AUTOSAR XML (schema 314)
package /ComponentType
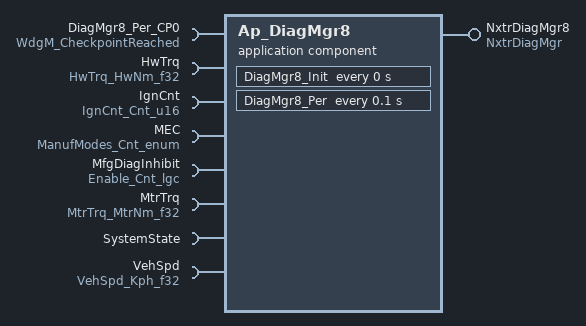
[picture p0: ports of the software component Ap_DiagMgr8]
  application software component type Ap_DiagMgr8
    provide port NxtrDiagMgr8: provided-interface=NxtrDiagMgr
      provided-com-specs:
        operation=GetNTCActive, queue-length=1
        operation=GetNTCFailed, queue-length=1
        operation=GetNTCStatus, queue-length=1
        operation=SetNTCStatus, queue-length=1
    8 x require port:
      DiagMgr8_Per_CP0: client-com-spec=CheckpointReached, required-interface=WdgM_CheckpointReached
      HwTrq: unqueued-receiver-com-spec{data-element=HwNm_f32, init-value=D_ZERO_ULS_F32}, required-interface=HwTrq_HwNm_f32
      IgnCnt: unqueued-receiver-com-spec{data-element=Cnt_u16, init-value=D_ZERO_CNT_U16}, required-interface=IgnCnt_Cnt_u16
      MEC: unqueued-receiver-com-spec{data-element=Cnt_enum, init-value=D_MANUFMODEINIT_CNT_ENUM}, required-interface=ManufModes_Cnt_enum
      MfgDiagInhibit: unqueued-receiver-com-spec{data-element=Cnt_lgc, init-value=D_FALSE_CNT_LGC}, required-interface=Enable_Cnt_lgc
      MtrTrq: unqueued-receiver-com-spec{data-element=MtrNm_f32, init-value=D_ZERO_ULS_F32}, required-interface=MtrTrq_MtrNm_f32
      SystemState: required-interface=SystemState
      VehSpd: unqueued-receiver-com-spec{data-element=Kph_f32, init-value=D_ZERO_ULS_F32}, required-interface=VehSpd_Kph_f32
  internal behavior Ap_DiagMgr8_InternalBehavior: component=Ap_DiagMgr8
    timing event DiagMgr8_InitEvent: start-on-event=DiagMgr8_Init, period=0
    timing event TMT_DiagMgr8_Per: start-on-event=DiagMgr8_Per, period=0.1
    mode switch event MST_DiagMgr8_Trns_0: start-on-event=DiagMgr8_Trns, activation=EXIT, mode=SystemState.Mode.OFF
    4 x operation invoked event:
      OIT_NxtrDiagMgr8_GetNTCActive_NxtrDiagMgr8_GetNTCActive: start-on-event=NxtrDiagMgr8_GetNTCActive, operation=NxtrDiagMgr8.GetNTCActive
      OIT_NxtrDiagMgr8_GetNTCFailed_NxtrDiagMgr8_GetNTCFailed: start-on-event=NxtrDiagMgr8_GetNTCFailed, operation=NxtrDiagMgr8.GetNTCFailed
      OIT_NxtrDiagMgr8_GetNTCStatus_NxtrDiagMgr8_GetNTCStatus: start-on-event=NxtrDiagMgr8_GetNTCStatus, operation=NxtrDiagMgr8.GetNTCStatus
      OIT_NxtrDiagMgr8_SetNTCStatus_NxtrDiagMgr8_SetNTCStatus: start-on-event=NxtrDiagMgr8_SetNTCStatus, operation=NxtrDiagMgr8.SetNTCStatus
    port-api-options:
      enable-take-address=false, indirect-api=false, port=DiagMgr8_Per_CP0
      enable-take-address=false, indirect-api=false, port=HwTrq
      enable-take-address=false, indirect-api=false, port=IgnCnt
      enable-take-address=false, indirect-api=false, port=MEC
      enable-take-address=false, indirect-api=false, port=MfgDiagInhibit
      enable-take-address=false, indirect-api=false, port=MtrTrq
      enable-take-address=false, indirect-api=false, port=NxtrDiagMgr8
      enable-take-address=false, indirect-api=false, port=SystemState
      enable-take-address=false, indirect-api=false, port=VehSpd
    7 x runnable:
      DiagMgr8_Init
      DiagMgr8_Per
        sync call SC_DiagMgr8_Per_CP0_CheckpointReached: operation=DiagMgr8_Per_CP0.CheckpointReached, timeout=0
      DiagMgr8_Trns
      NxtrDiagMgr8_GetNTCActive: can-be-invoked-concurrently=true
      NxtrDiagMgr8_GetNTCFailed: can-be-invoked-concurrently=true
      NxtrDiagMgr8_GetNTCStatus: can-be-invoked-concurrently=true
      NxtrDiagMgr8_SetNTCStatus: can-be-invoked-concurrently=true
        6 x data receive point:
          REC_HwTrq_HwNm_f32: data-element=HwTrq.HwNm_f32
          REC_IgnCnt_Cnt_u16: data-element=IgnCnt.Cnt_u16
          REC_MEC_Cnt_enum: data-element=MEC.Cnt_enum
          REC_MfgDiagInhibit_Cnt_lgc: data-element=MfgDiagInhibit.Cnt_lgc
          REC_MtrTrq_MtrNm_f32: data-element=MtrTrq.MtrNm_f32
          REC_VehSpd_Kph_f32: data-element=VehSpd.Kph_f32
  swc implementation Ap_DiagMgr8_Implementation: behavior=Ap_DiagMgr8_InternalBehavior
    code-descriptors:
      code Code: type=SRC
